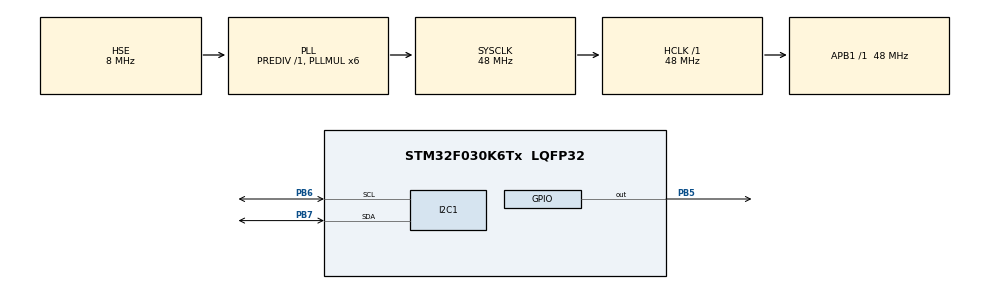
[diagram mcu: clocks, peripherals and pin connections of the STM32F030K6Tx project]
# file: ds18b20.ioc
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Mcu.Family=STM32F0
Mcu.Name=STM32F030K6Tx
Mcu.Package=LQFP32
NVIC.I2C1_IRQn=true\:0\:0\:false\:false\:true\:true\:true\:true
NVIC.TIM16_IRQn=true\:0\:0\:false\:false\:true\:true\:true\:true
PA13.Mode=Serial_Wire
PA13.Signal=SYS_SWDIO
PA14.Mode=Serial_Wire
PA14.Signal=SYS_SWCLK
PB5.Signal=GPIO_Output
PB6.Mode=I2C
PB6.Signal=I2C1_SCL
PB7.Mode=I2C
PB7.Signal=I2C1_SDA
PF0-OSC_IN.Mode=HSE-External-Oscillator
PF0-OSC_IN.Signal=RCC_OSC_IN
PF1-OSC_OUT.Mode=HSE-External-Oscillator
PF1-OSC_OUT.Signal=RCC_OSC_OUT
ProjectManager.HeapSize=0x200
ProjectManager.StackSize=0x400
ProjectManager.TargetToolchain=STM32CubeIDE
RCC.AHBFreq_Value=48000000
RCC.APB1Freq_Value=48000000
RCC.APB1TimFreq_Value=48000000
RCC.EnbaleCSS=true
RCC.HCLKFreq_Value=48000000
RCC.PLLMUL=RCC_PLL_MUL6
RCC.PLLSourceVirtual=RCC_PLLSOURCE_HSE
RCC.SYSCLKFreq_VALUE=48000000
RCC.SYSCLKSource=RCC_SYSCLKSOURCE_PLLCLK
TIM14.Period=0xffff-1
TIM14.Prescaler=48-1
TIM16.Period=1000-1
TIM16.Prescaler=4800-1
VP_TIM14_VS_ClockSourceINT.Mode=Enable_Timer
VP_TIM16_VS_ClockSourceINT.Mode=Enable_Timer
board=custom

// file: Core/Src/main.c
/* USER CODE BEGIN Header */
/**
  ******************************************************************************
  * @file           : main.c
  * @brief          : Main program body
  ******************************************************************************
  * @attention
  *
  * Copyright (c) 2023 STMicroelectronics.
  * All rights reserved.
  *
  * This software is licensed under terms that can be found in the LICENSE file
  * in the root directory of this software component.
  * If no LICENSE file comes with this software, it is provided AS-IS.
  *
  ******************************************************************************
  */
/* USER CODE END Header */
#include "main.h"
#include "i2c.h"
#include "tim.h"
#include "gpio.h"

/* USER CODE BEGIN PV */

/* Variables for AHT10 */
uint8_t AHT10_RX_Data[6];
uint32_t AHT10_ADC_Raw;
float AHT10_Temperature;
float AHT10_Humidity;
uint8_t AHT10_TmpHum_Cmd[3] = {0xAC, 0x33, 0x00};

#define AHT10_ADRESS (0x38 << 1) // 0b1110000; Adress[7-bit]Wite/Read[1-bit]

/* Additional vars */
uint8_t T_100ms = 255;
uint8_t AHT10_Switcher = 255;

/* USER CODE END PV */

void SystemClock_Config(void);

/* USER CODE BEGIN 0 */

void delay (uint16_t time)
{
	__HAL_TIM_SET_COUNTER(&htim14,0);
	while (__HAL_TIM_GET_COUNTER(&htim14)<time);
}

uint8_t  Temp_byte1, Temp_byte2;
uint16_t TEMP;

float Temperature = 0;
uint8_t Presence = 0;

void Set_Pin_Output (GPIO_TypeDef *GPIOx, uint16_t GPIO_Pin)
{
	GPIO_InitTypeDef GPIO_InitStruct = {0};
	GPIO_InitStruct.Pin = GPIO_Pin;
	GPIO_InitStruct.Mode = GPIO_MODE_OUTPUT_PP;
	GPIO_InitStruct.Speed = GPIO_SPEED_FREQ_LOW;
	HAL_GPIO_Init(GPIOx, &GPIO_InitStruct);
}

void Set_Pin_Input (GPIO_TypeDef *GPIOx, uint16_t GPIO_Pin)
{
	GPIO_InitTypeDef GPIO_InitStruct = {0};
	GPIO_InitStruct.Pin = GPIO_Pin;
	GPIO_InitStruct.Mode = GPIO_MODE_INPUT;
	GPIO_InitStruct.Pull = GPIO_PULLUP;
	HAL_GPIO_Init(GPIOx, &GPIO_InitStruct);
}

/*********************************** DS18B20 FUNCTIONS ****************************************/

#define DS18B20_PORT GPIOB
#define DS18B20_PIN GPIO_PIN_5

uint8_t DS18B20_Start (void)
{
	uint8_t Response = 0;
	Set_Pin_Output(DS18B20_PORT, DS18B20_PIN);   // set the pin as output
	HAL_GPIO_WritePin (DS18B20_PORT, DS18B20_PIN, 0);  // pull the pin low
	delay (480);   // delay according to datasheet

	Set_Pin_Input(DS18B20_PORT, DS18B20_PIN);    // set the pin as input
	delay (80);    // delay according to datasheet

	if (!(HAL_GPIO_ReadPin (DS18B20_PORT, DS18B20_PIN))) Response = 1;    // if the pin is low i.e the presence pulse is detected
	else Response = -1;

	delay (400); // 480 us delay totally.

	return Response;
}

void DS18B20_Write (uint8_t data)
{
	Set_Pin_Output(DS18B20_PORT, DS18B20_PIN);  // set as output

	for (int i=0; i<8; i++)
	{

		if ((data & (1<<i))!=0)  // if the bit is high
		{
			// write 1

			Set_Pin_Output(DS18B20_PORT, DS18B20_PIN);  // set as output
			HAL_GPIO_WritePin (DS18B20_PORT, DS18B20_PIN, 0);  // pull the pin LOW
			delay (1);  // wait for 1 us

			Set_Pin_Input(DS18B20_PORT, DS18B20_PIN);  // set as input
			delay (50);  // wait for 60 us
		}

		else  // if the bit is low
		{
			// write 0

			Set_Pin_Output(DS18B20_PORT, DS18B20_PIN);
			HAL_GPIO_WritePin (DS18B20_PORT, DS18B20_PIN, 0);  // pull the pin LOW
			delay (50);  // wait for 60 us

			Set_Pin_Input(DS18B20_PORT, DS18B20_PIN);
		}
	}
}

uint8_t DS18B20_Read (void)
{
	uint8_t value=0;

	Set_Pin_Input(DS18B20_PORT, DS18B20_PIN);

	for (int i=0;i<8;i++)
	{
		Set_Pin_Output(DS18B20_PORT, DS18B20_PIN);   // set as output

		HAL_GPIO_WritePin (DS18B20_PORT, DS18B20_PIN, 0);  // pull the data pin LOW
		delay (1);  // wait for > 1us

		Set_Pin_Input(DS18B20_PORT, DS18B20_PIN);  // set as input
		if (HAL_GPIO_ReadPin (DS18B20_PORT, DS18B20_PIN))  // if the pin is HIGH
		{
			value |= 1<<i;  // read = 1
		}
		delay (50);  // wait for 60 us
	}
	return value;
}

void DS18B20_TEMP()
{
	Presence = DS18B20_Start ();
	HAL_Delay (1);
	DS18B20_Write (0xCC);  // skip ROM
	DS18B20_Write (0x44);  // convert t
	HAL_Delay (800);

	Presence = DS18B20_Start ();
	HAL_Delay(1);
	DS18B20_Write (0xCC);  // skip ROM
	DS18B20_Write (0xBE);  // Read Scratch-pad

	Temp_byte1 = DS18B20_Read();
	Temp_byte2 = DS18B20_Read();
	TEMP = (Temp_byte2<<8)|Temp_byte1;
	Temperature = (float)TEMP/16;
}

/*********************************** aht10 FUNCTIONS ****************************************/
void HAL_TIM_PeriodElapsedCallback(TIM_HandleTypeDef *htim)
{
 if(htim->Instance == TIM16)
 {
	/* Set every 100ms */
	T_100ms = 255;
 }
}

void AHT10_GET()
{
	if(T_100ms)
		  	{
		  		if(AHT10_Switcher)
		  			{
		  				HAL_I2C_Master_Transmit_IT(&hi2c1, AHT10_ADRESS, (uint8_t*)AHT10_TmpHum_Cmd, 3); /* Send command (trigger measuremetns) + parameters */
		  			}
		  		else
		  			{
		  				HAL_I2C_Master_Receive_IT(&hi2c1, AHT10_ADRESS, (uint8_t*)AHT10_RX_Data, 6); /* Receive data: STATUS[1]:HIMIDITY[2.5]:TEMPERATURE[2.5] */
		  			}

		  		if(~AHT10_RX_Data[0] & 0x80)
		  		{
		  			/* Convert to Temperature in °C */
		  			AHT10_ADC_Raw = (((uint32_t)AHT10_RX_Data[3] & 15) << 16) | ((uint32_t)AHT10_RX_Data[4] << 8) | AHT10_RX_Data[5];
		  			AHT10_Temperature = (float)(AHT10_ADC_Raw * 200.00 / 1048576.00) - 50.00;

		  			/* Convert to Relative Humidity in % */
		  			AHT10_ADC_Raw = ((uint32_t)AHT10_RX_Data[1] << 12) | ((uint32_t)AHT10_RX_Data[2] << 4) | (AHT10_RX_Data[3] >> 4);
		  			AHT10_Humidity = (float)(AHT10_ADC_Raw*100.00/1048576.00);
		  		}

		  		AHT10_Switcher = ~AHT10_Switcher; /* Invert */
		  		//GPIOC->ODR ^= GPIO_ODR_ODR13; /* Green LED */
		  		T_100ms = 0; /* Nulify */
		  	}
}
/* USER CODE END 0 */

int main(void)
{

  /* MCU Configuration--------------------------------------------------------*/

  /* Reset of all peripherals, Initializes the Flash interface and the Systick. */
  HAL_Init();

  /* Configure the system clock */
  SystemClock_Config();

  /* Initialize all configured peripherals */
  MX_GPIO_Init();
  MX_TIM14_Init();
  MX_I2C1_Init();
  MX_TIM16_Init();
  /* USER CODE BEGIN 2 */

HAL_TIM_Base_Start(&htim14);
HAL_TIM_Base_Start_IT(&htim16);
  /* USER CODE END 2 */

  /* Infinite loop */
  /* USER CODE BEGIN WHILE */
  while (1)
  {
	  /********************* DS18B20 *******************/
	  AHT10_GET();
	  DS18B20_TEMP();
	  //HAL_Delay(50);
    /* USER CODE END WHILE */

  }
}

void SystemClock_Config(void)
{
  RCC_OscInitTypeDef RCC_OscInitStruct = {0};
  RCC_ClkInitTypeDef RCC_ClkInitStruct = {0};
  RCC_PeriphCLKInitTypeDef PeriphClkInit = {0};

  /** Initializes the RCC Oscillators according to the specified parameters
  * in the RCC_OscInitTypeDef structure.
  */
  RCC_OscInitStruct.OscillatorType = RCC_OSCILLATORTYPE_HSI|RCC_OSCILLATORTYPE_HSE;
  RCC_OscInitStruct.HSEState = RCC_HSE_ON;
  RCC_OscInitStruct.HSIState = RCC_HSI_ON;
  RCC_OscInitStruct.HSICalibrationValue = RCC_HSICALIBRATION_DEFAULT;
  RCC_OscInitStruct.PLL.PLLState = RCC_PLL_ON;
  RCC_OscInitStruct.PLL.PLLSource = RCC_PLLSOURCE_HSE;
  RCC_OscInitStruct.PLL.PLLMUL = RCC_PLL_MUL6;
  RCC_OscInitStruct.PLL.PREDIV = RCC_PREDIV_DIV1;
  if (HAL_RCC_OscConfig(&RCC_OscInitStruct) != HAL_OK)
  {
    Error_Handler();
  }

  /** Initializes the CPU, AHB and APB buses clocks
  */
  RCC_ClkInitStruct.ClockType = RCC_CLOCKTYPE_HCLK|RCC_CLOCKTYPE_SYSCLK
                              |RCC_CLOCKTYPE_PCLK1;
  RCC_ClkInitStruct.SYSCLKSource = RCC_SYSCLKSOURCE_PLLCLK;
  RCC_ClkInitStruct.AHBCLKDivider = RCC_SYSCLK_DIV1;
  RCC_ClkInitStruct.APB1CLKDivider = RCC_HCLK_DIV1;

  if (HAL_RCC_ClockConfig(&RCC_ClkInitStruct, FLASH_LATENCY_1) != HAL_OK)
  {
    Error_Handler();
  }
  PeriphClkInit.PeriphClockSelection = RCC_PERIPHCLK_I2C1;
  PeriphClkInit.I2c1ClockSelection = RCC_I2C1CLKSOURCE_HSI;
  if (HAL_RCCEx_PeriphCLKConfig(&PeriphClkInit) != HAL_OK)
  {
    Error_Handler();
  }

  /** Enables the Clock Security System
  */
  HAL_RCC_EnableCSS();
}

void Error_Handler(void)
{
  __disable_irq();
  while (1)
  {
  }
}
